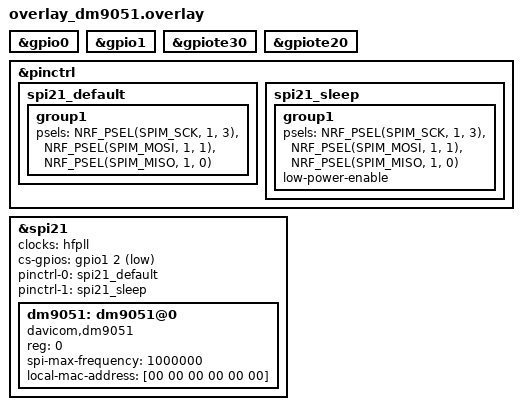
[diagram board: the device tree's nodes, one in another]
/* Ensure GPIO0, GPIO1 and their GPIOTE instances are enabled */
&gpio0 {
	status = "okay";
};

&gpio1 {
	status = "okay";
};

&gpiote30 {
	status = "okay";
};

&gpiote20 {
	status = "okay";
};

&pinctrl {
	spi21_default: spi21_default {
		group1 {
			psels = <NRF_PSEL(SPIM_SCK, 1, 3)>,
				<NRF_PSEL(SPIM_MOSI, 1, 1)>,
				<NRF_PSEL(SPIM_MISO, 1, 0)>;
		};
	};

	spi21_sleep: spi21_sleep {
		group1 {
			psels = <NRF_PSEL(SPIM_SCK, 1, 3)>,
				<NRF_PSEL(SPIM_MOSI, 1, 1)>,
				<NRF_PSEL(SPIM_MISO, 1, 0)>;
			low-power-enable;
		};
	};
};

&spi21 {
	status = "okay";
	clocks = <&hfpll>;
	cs-gpios = <&gpio1 2 GPIO_ACTIVE_LOW>;  /* CS on P1.2 */
	pinctrl-0 = <&spi21_default>;
	pinctrl-1 = <&spi21_sleep>;
	pinctrl-names = "default", "sleep";
	
	dm9051: dm9051@0 {
		compatible = "davicom,dm9051";
		reg = <0>;
		spi-max-frequency = <1000000>;  /* 1MHz - minimum for debugging */
		/* int-gpios = <&gpio0 3 GPIO_ACTIVE_LOW>; */
		/* reset-gpios = <&gpio2 0 GPIO_ACTIVE_LOW>; */
		
		/* Local MAC address */
		local-mac-address = [00 00 00 00 00 00]; /* [00 11 22 33 44 55]; */
	};
};
